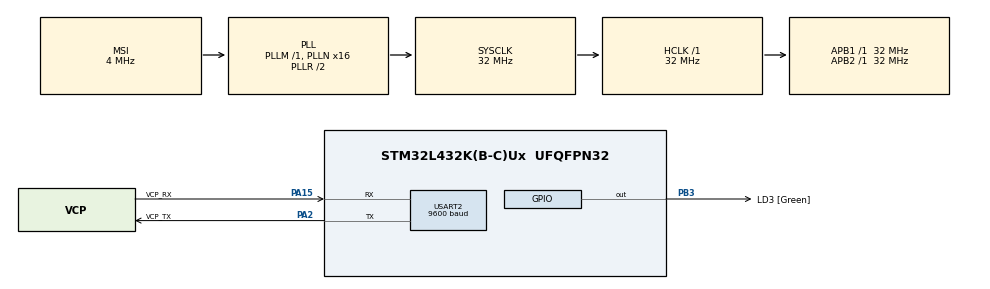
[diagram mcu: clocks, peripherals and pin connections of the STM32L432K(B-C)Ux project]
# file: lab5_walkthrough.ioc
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ADC1.Channel-0\#ChannelRegularConversion=ADC_CHANNEL_VREFINT
ADC1.NbrOfConversionFlag=1
ADC1.OffsetNumber-0\#ChannelRegularConversion=ADC_OFFSET_NONE
ADC1.Rank-0\#ChannelRegularConversion=1
ADC1.SamplingTime-0\#ChannelRegularConversion=ADC_SAMPLETIME_2CYCLES_5
ADC1.master=1
Mcu.Family=STM32L4
Mcu.Name=STM32L432K(B-C)Ux
Mcu.Package=UFQFPN32
NVIC.PriorityGroup=NVIC_PRIORITYGROUP_4
NVIC.RTC_Alarm_IRQn=true\:0\:0\:false\:false\:true\:true\:true
NVIC.USART2_IRQn=true\:0\:0\:false\:false\:true\:true\:true
PA0.GPIO_Label=MCO [High speed clock in]
PA0.Mode=HSE-External-Clock-Source-for-LittleOrca
PA0.Signal=RCC_CK_IN
PA13\ (JTMS-SWDIO).GPIO_Label=SWDIO
PA13\ (JTMS-SWDIO).Mode=Serial_Wire
PA13\ (JTMS-SWDIO).Signal=SYS_JTMS-SWDIO
PA14\ (JTCK-SWCLK).GPIO_Label=SWCLK
PA14\ (JTCK-SWCLK).Mode=Serial_Wire
PA14\ (JTCK-SWCLK).Signal=SYS_JTCK-SWCLK
PA15\ (JTDI).GPIO_Label=VCP_RX
PA15\ (JTDI).Mode=Asynchronous
PA15\ (JTDI).Signal=USART2_RX
PA2.GPIO_Label=VCP_TX
PA2.Mode=Asynchronous
PA2.Signal=USART2_TX
PA5.Signal=S_TIM2_CH1
PB3\ (JTDO-TRACESWO).GPIO_Label=LD3 [Green]
PB3\ (JTDO-TRACESWO).Signal=GPIO_Output
PC14-OSC32_IN\ (PC14).Mode=LSE-External-Oscillator
PC14-OSC32_IN\ (PC14).Signal=RCC_OSC32_IN
PC15-OSC32_OUT\ (PC15).Mode=LSE-External-Oscillator
PC15-OSC32_OUT\ (PC15).Signal=RCC_OSC32_OUT
ProjectManager.HeapSize=0x200
ProjectManager.StackSize=0x400
ProjectManager.TargetToolchain=Makefile
RCC.ADCFreq_Value=32000000
RCC.AHBFreq_Value=32000000
RCC.APB1Freq_Value=32000000
RCC.APB1TimFreq_Value=32000000
RCC.APB2Freq_Value=32000000
RCC.APB2TimFreq_Value=32000000
RCC.CortexFreq_Value=32000000
RCC.HCLKFreq_Value=32000000
RCC.HSE_VALUE=8000000
RCC.HSI16_VALUE=16000000
RCC.HSI48_VALUE=48000000
RCC.HSI_VALUE=16000000
RCC.MSI_VALUE=4000000
RCC.PLLMUL=RCC_PLLMUL_4
RCC.PLLN=16
RCC.PLLSAI1N=16
RCC.SYSCLKFreq_VALUE=32000000
RCC.SYSCLKSource=RCC_SYSCLKSOURCE_PLLCLK
RCC.USBFreq_Value=32000000
RCC.VCOOutputFreq_Value=64000000
RTC.Alarm=RTC_ALARM_A
RTC.AlarmMaskDateWeekDay=RTC_ALARMMASK_DATEWEEKDAY
RTC.AlarmMaskHours=RTC_ALARMMASK_HOURS
RTC.AlarmMaskMinutes=RTC_ALARMMASK_MINUTES
RTC.Seconds_A=30
SH.S_TIM2_CH1.0=TIM2_CH1
USART2.BaudRate=9600
USART2.VirtualMode-Asynchronous=VM_ASYNC
VP_ADC1_TempSens_Input.Mode=IN-TempSens
VP_ADC1_Vref_Input.Mode=IN-Vrefint
VP_RTC_VS_RTC_Activate.Mode=RTC_Enabled
VP_RTC_VS_RTC_Alarm_A_Intern.Mode=Alarm A
VP_RTC_VS_RTC_Calendar.Mode=RTC_Calendar
board=NUCLEO-L432KC

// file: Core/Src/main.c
/* USER CODE BEGIN Header */
/**
  ******************************************************************************
  * @file           : main.c
  * @brief          : Main program body
  ******************************************************************************
  * @attention
  *
  * <h2><center>&copy; Copyright (c) 2021 STMicroelectronics.
  * All rights reserved.</center></h2>
  *
  * This software component is licensed by ST under BSD 3-Clause license,
  * the "License"; You may not use this file except in compliance with the
  * License. You may obtain a copy of the License at:
  *                        opensource.org/licenses/BSD-3-Clause
  *
  ******************************************************************************
  */
/* USER CODE END Header */
#include "main.h"

/* USER CODE BEGIN Includes */
#include "retarget.h"
#include <stdio.h>
#include <string.h>
#include <stm32l4xx_ll_usart.h>
#include "queue.h"
#include "command.h"
#include "led.h"
/* USER CODE END Includes */

/* USER CODE BEGIN PD */
#define MAX_BUF 80

/* USER CODE END PD */

ADC_HandleTypeDef hadc1;

RTC_HandleTypeDef hrtc;

UART_HandleTypeDef huart2;

/* USER CODE BEGIN PV */
queue_t rx_queue;
int alarm_flag = 0;
/* USER CODE END PV */

void SystemClock_Config(void);
static void MX_GPIO_Init(void);
static void MX_USART2_UART_Init(void);
static void MX_RTC_Init(void);
static void MX_ADC1_Init(void);

int main(void)
{
  /* USER CODE BEGIN 1 */
  uint8_t command[MAX_COMMAND_LEN];
  int command_length;

  /* USER CODE END 1 */

  /* MCU Configuration--------------------------------------------------------*/

  /* Reset of all peripherals, Initializes the Flash interface and the Systick. */
  HAL_Init();

  /* Configure the system clock */
  SystemClock_Config();

  /* Initialize all configured peripherals */
  MX_GPIO_Init();
  MX_USART2_UART_Init();
  MX_RTC_Init();
  MX_ADC1_Init();
  /* USER CODE BEGIN 2 */

  RetargetInit(&huart2);
  printf("\n\r\n\rE314 System Boot\n\r");
  printf("Version: %s\n\r",VERSION);
  /* USER CODE END 2 */

  /* Infinite loop */
  /* USER CODE BEGIN WHILE */
  prompt();
  while (1)
  {
    /* USER CODE END WHILE */

    /* USER CODE BEGIN 3 */
    // Command Interpreter
    if (get_command(command)) {
      command_length = delspace(command);
      if (command_length != -1) {
        if(execute_command(command)) {
          printf("NOK\n\r");
          prompt();
        }
        else {
          prompt();
        }
      }
      else {
        printf("NOK\n\r");
        prompt();
      }

    }
    if (alarm_flag) {
      alarm_flag = 0;
      lon();
      HAL_Delay(100);
      lof();
    }
    // Check if time to sample light sensor
  }
  /* USER CODE END 3 */
}

void SystemClock_Config(void)
{
  RCC_OscInitTypeDef RCC_OscInitStruct = {0};
  RCC_ClkInitTypeDef RCC_ClkInitStruct = {0};
  RCC_PeriphCLKInitTypeDef PeriphClkInit = {0};

  /** Configure LSE Drive Capability
  */
  HAL_PWR_EnableBkUpAccess();
  __HAL_RCC_LSEDRIVE_CONFIG(RCC_LSEDRIVE_LOW);
  /** Initializes the RCC Oscillators according to the specified parameters
  * in the RCC_OscInitTypeDef structure.
  */
  RCC_OscInitStruct.OscillatorType = RCC_OSCILLATORTYPE_LSI|RCC_OSCILLATORTYPE_LSE
                              |RCC_OSCILLATORTYPE_MSI;
  RCC_OscInitStruct.LSEState = RCC_LSE_ON;
  RCC_OscInitStruct.LSIState = RCC_LSI_ON;
  RCC_OscInitStruct.MSIState = RCC_MSI_ON;
  RCC_OscInitStruct.MSICalibrationValue = 0;
  RCC_OscInitStruct.MSIClockRange = RCC_MSIRANGE_6;
  RCC_OscInitStruct.PLL.PLLState = RCC_PLL_ON;
  RCC_OscInitStruct.PLL.PLLSource = RCC_PLLSOURCE_MSI;
  RCC_OscInitStruct.PLL.PLLM = 1;
  RCC_OscInitStruct.PLL.PLLN = 16;
  RCC_OscInitStruct.PLL.PLLP = RCC_PLLP_DIV7;
  RCC_OscInitStruct.PLL.PLLQ = RCC_PLLQ_DIV2;
  RCC_OscInitStruct.PLL.PLLR = RCC_PLLR_DIV2;
  if (HAL_RCC_OscConfig(&RCC_OscInitStruct) != HAL_OK)
  {
    Error_Handler();
  }
  /** Initializes the CPU, AHB and APB buses clocks
  */
  RCC_ClkInitStruct.ClockType = RCC_CLOCKTYPE_HCLK|RCC_CLOCKTYPE_SYSCLK
                              |RCC_CLOCKTYPE_PCLK1|RCC_CLOCKTYPE_PCLK2;
  RCC_ClkInitStruct.SYSCLKSource = RCC_SYSCLKSOURCE_PLLCLK;
  RCC_ClkInitStruct.AHBCLKDivider = RCC_SYSCLK_DIV1;
  RCC_ClkInitStruct.APB1CLKDivider = RCC_HCLK_DIV1;
  RCC_ClkInitStruct.APB2CLKDivider = RCC_HCLK_DIV1;

  if (HAL_RCC_ClockConfig(&RCC_ClkInitStruct, FLASH_LATENCY_1) != HAL_OK)
  {
    Error_Handler();
  }
  PeriphClkInit.PeriphClockSelection = RCC_PERIPHCLK_RTC|RCC_PERIPHCLK_USART2
                              |RCC_PERIPHCLK_ADC;
  PeriphClkInit.Usart2ClockSelection = RCC_USART2CLKSOURCE_PCLK1;
  PeriphClkInit.AdcClockSelection = RCC_ADCCLKSOURCE_PLLSAI1;
  PeriphClkInit.RTCClockSelection = RCC_RTCCLKSOURCE_LSI;
  PeriphClkInit.PLLSAI1.PLLSAI1Source = RCC_PLLSOURCE_MSI;
  PeriphClkInit.PLLSAI1.PLLSAI1M = 1;
  PeriphClkInit.PLLSAI1.PLLSAI1N = 16;
  PeriphClkInit.PLLSAI1.PLLSAI1P = RCC_PLLP_DIV7;
  PeriphClkInit.PLLSAI1.PLLSAI1Q = RCC_PLLQ_DIV2;
  PeriphClkInit.PLLSAI1.PLLSAI1R = RCC_PLLR_DIV2;
  PeriphClkInit.PLLSAI1.PLLSAI1ClockOut = RCC_PLLSAI1_ADC1CLK;
  if (HAL_RCCEx_PeriphCLKConfig(&PeriphClkInit) != HAL_OK)
  {
    Error_Handler();
  }
  /** Configure the main internal regulator output voltage
  */
  if (HAL_PWREx_ControlVoltageScaling(PWR_REGULATOR_VOLTAGE_SCALE1) != HAL_OK)
  {
    Error_Handler();
  }
  /** Enable MSI Auto calibration
  */
  HAL_RCCEx_EnableMSIPLLMode();
}

static void MX_ADC1_Init(void)
{

  ADC_ChannelConfTypeDef sConfig = {0};

  /** Common config
  */
  hadc1.Instance = ADC1;
  hadc1.Init.ClockPrescaler = ADC_CLOCK_ASYNC_DIV1;
  hadc1.Init.Resolution = ADC_RESOLUTION_12B;
  hadc1.Init.DataAlign = ADC_DATAALIGN_RIGHT;
  hadc1.Init.ScanConvMode = ADC_SCAN_DISABLE;
  hadc1.Init.EOCSelection = ADC_EOC_SINGLE_CONV;
  hadc1.Init.LowPowerAutoWait = DISABLE;
  hadc1.Init.ContinuousConvMode = DISABLE;
  hadc1.Init.NbrOfConversion = 1;
  hadc1.Init.DiscontinuousConvMode = DISABLE;
  hadc1.Init.ExternalTrigConv = ADC_SOFTWARE_START;
  hadc1.Init.ExternalTrigConvEdge = ADC_EXTERNALTRIGCONVEDGE_NONE;
  hadc1.Init.DMAContinuousRequests = DISABLE;
  hadc1.Init.Overrun = ADC_OVR_DATA_PRESERVED;
  hadc1.Init.OversamplingMode = DISABLE;
  if (HAL_ADC_Init(&hadc1) != HAL_OK)
  {
    Error_Handler();
  }
  /** Configure Regular Channel
  */
  sConfig.Channel = ADC_CHANNEL_VREFINT;
  sConfig.Rank = ADC_REGULAR_RANK_1;
  sConfig.SamplingTime = ADC_SAMPLETIME_2CYCLES_5;
  sConfig.SingleDiff = ADC_SINGLE_ENDED;
  sConfig.OffsetNumber = ADC_OFFSET_NONE;
  sConfig.Offset = 0;
  if (HAL_ADC_ConfigChannel(&hadc1, &sConfig) != HAL_OK)
  {
    Error_Handler();
  }

}

static void MX_RTC_Init(void)
{

  RTC_TimeTypeDef sTime = {0};
  RTC_DateTypeDef sDate = {0};
  RTC_AlarmTypeDef sAlarm = {0};

  /** Initialize RTC Only
  */
  hrtc.Instance = RTC;
  hrtc.Init.HourFormat = RTC_HOURFORMAT_24;
  hrtc.Init.AsynchPrediv = 127;
  hrtc.Init.SynchPrediv = 255;
  hrtc.Init.OutPut = RTC_OUTPUT_DISABLE;
  hrtc.Init.OutPutRemap = RTC_OUTPUT_REMAP_NONE;
  hrtc.Init.OutPutPolarity = RTC_OUTPUT_POLARITY_HIGH;
  hrtc.Init.OutPutType = RTC_OUTPUT_TYPE_OPENDRAIN;
  if (HAL_RTC_Init(&hrtc) != HAL_OK)
  {
    Error_Handler();
  }

  /** Initialize RTC and set the Time and Date
  */
  sTime.Hours = 0x0;
  sTime.Minutes = 0x0;
  sTime.Seconds = 0x0;
  sTime.DayLightSaving = RTC_DAYLIGHTSAVING_NONE;
  sTime.StoreOperation = RTC_STOREOPERATION_RESET;
  if (HAL_RTC_SetTime(&hrtc, &sTime, RTC_FORMAT_BCD) != HAL_OK)
  {
    Error_Handler();
  }
  sDate.WeekDay = RTC_WEEKDAY_MONDAY;
  sDate.Month = RTC_MONTH_JANUARY;
  sDate.Date = 0x1;
  sDate.Year = 0x0;

  if (HAL_RTC_SetDate(&hrtc, &sDate, RTC_FORMAT_BCD) != HAL_OK)
  {
    Error_Handler();
  }
  /** Enable the Alarm A
  */
  sAlarm.AlarmTime.Hours = 0x0;
  sAlarm.AlarmTime.Minutes = 0x0;
  sAlarm.AlarmTime.Seconds = 0x30;
  sAlarm.AlarmTime.SubSeconds = 0x0;
  sAlarm.AlarmTime.DayLightSaving = RTC_DAYLIGHTSAVING_NONE;
  sAlarm.AlarmTime.StoreOperation = RTC_STOREOPERATION_RESET;
  sAlarm.AlarmMask = RTC_ALARMMASK_DATEWEEKDAY|RTC_ALARMMASK_HOURS
                              |RTC_ALARMMASK_MINUTES;
  sAlarm.AlarmSubSecondMask = RTC_ALARMSUBSECONDMASK_ALL;
  sAlarm.AlarmDateWeekDaySel = RTC_ALARMDATEWEEKDAYSEL_DATE;
  sAlarm.AlarmDateWeekDay = 0x1;
  sAlarm.Alarm = RTC_ALARM_A;
  if (HAL_RTC_SetAlarm_IT(&hrtc, &sAlarm, RTC_FORMAT_BCD) != HAL_OK)
  {
    Error_Handler();
  }

}

static void MX_USART2_UART_Init(void)
{

  huart2.Instance = USART2;
  huart2.Init.BaudRate = 9600;
  huart2.Init.WordLength = UART_WORDLENGTH_8B;
  huart2.Init.StopBits = UART_STOPBITS_1;
  huart2.Init.Parity = UART_PARITY_NONE;
  huart2.Init.Mode = UART_MODE_TX_RX;
  huart2.Init.HwFlowCtl = UART_HWCONTROL_NONE;
  huart2.Init.OverSampling = UART_OVERSAMPLING_16;
  huart2.Init.OneBitSampling = UART_ONE_BIT_SAMPLE_DISABLE;
  huart2.AdvancedInit.AdvFeatureInit = UART_ADVFEATURE_NO_INIT;
  if (HAL_UART_Init(&huart2) != HAL_OK)
  {
    Error_Handler();
  }
  /* USER CODE BEGIN USART2_Init 2 */

  LL_USART_EnableIT_RXNE(USART2);

  /* USER CODE END USART2_Init 2 */

}

static void MX_GPIO_Init(void)
{
  GPIO_InitTypeDef GPIO_InitStruct = {0};

  /* GPIO Ports Clock Enable */
  __HAL_RCC_GPIOC_CLK_ENABLE();
  __HAL_RCC_GPIOA_CLK_ENABLE();
  __HAL_RCC_GPIOB_CLK_ENABLE();

  /*Configure GPIO pin Output Level */
  HAL_GPIO_WritePin(LD3_GPIO_Port, LD3_Pin, GPIO_PIN_RESET);

  /*Configure GPIO pin : PA5 */
  GPIO_InitStruct.Pin = GPIO_PIN_5;
  GPIO_InitStruct.Mode = GPIO_MODE_AF_PP;
  GPIO_InitStruct.Pull = GPIO_NOPULL;
  GPIO_InitStruct.Speed = GPIO_SPEED_FREQ_LOW;
  GPIO_InitStruct.Alternate = GPIO_AF1_TIM2;
  HAL_GPIO_Init(GPIOA, &GPIO_InitStruct);

  /*Configure GPIO pin : LD3_Pin */
  GPIO_InitStruct.Pin = LD3_Pin;
  GPIO_InitStruct.Mode = GPIO_MODE_OUTPUT_PP;
  GPIO_InitStruct.Pull = GPIO_NOPULL;
  GPIO_InitStruct.Speed = GPIO_SPEED_FREQ_LOW;
  HAL_GPIO_Init(LD3_GPIO_Port, &GPIO_InitStruct);

}

void Error_Handler(void)
{
  __disable_irq();
  while (1)
  {
  }
}

/************************ (C) COPYRIGHT STMicroelectronics *****END OF FILE****/
